# GD32G5x3 register map
File version: 1.0
CPU: CM33 r2p1, little endian, MPU, FPU, 4 interrupt priority bits
Registers are 32-bit, read-write, reset 0x0 unless marked. A register's access mark holds for its fields unless they carry their own. Offsets are from the block's base; [hi:lo] are bit positions; {n}, {i} and the like mark numbered series.

## CAU — Cryptographic Acceleration Unit
Base 0x48021000
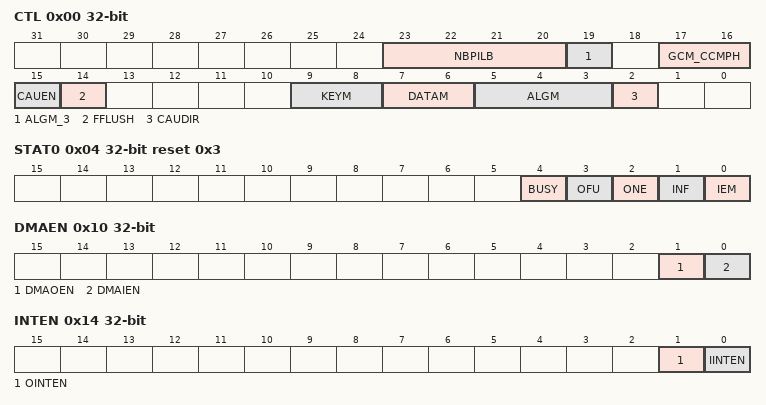
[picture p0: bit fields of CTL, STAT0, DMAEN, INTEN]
0x00 CTL access per field — Control register
  [23:20] NBPILB rw — Number of bytes padding in last block of payload
  [19] ALGM_3 rw — Encryption/decryption algorithm mode bit 3
  [17:16] GCM_CCMPH rw — GCM CCM phase
  [15] CAUEN rw — CAU Enable
  [14] FFLUSH wo — Flush FIFO
  [9:8] KEYM rw — AES key size mode configuration
  [7:6] DATAM rw — Data swapping type mode configuration
  [5:3] ALGM rw — Encryption/decryption algorithm mode bit 0 to bit 2
  [2] CAUDIR rw — CAU direction
0x04 STAT0 ro reset 0x3 — Status register 0
  [4] BUSY — Busy bit
  [3] OFU — Output FIFO is full
  [2] ONE — Output FIFO is not empty
  [1] INF — Input FIFO is not full
  [0] IEM — Input FIFO is empty
0x08 DI — Data input register
  [31:0] DI — Data input
0x0C DO ro — Data output register
  [31:0] DO — Data output
0x10 DMAEN — DMA enable register
  [1] DMAOEN — DMA output enable
  [0] DMAIEN — DMA input enable
0x14 INTEN — Interrupt enable register
  [1] OINTEN — OUT FIFO interrupt enable
  [0] IINTEN — IN FIFO interrupt enable
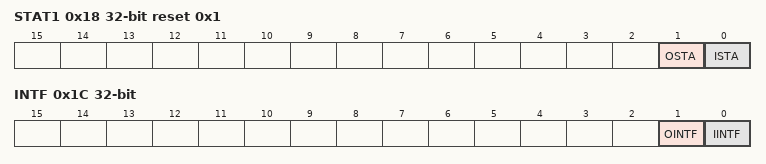
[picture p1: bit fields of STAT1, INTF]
0x18 STAT1 ro reset 0x1 — Status register 1
  [1] OSTA — OUT FIFO interrupt status
  [0] ISTA — IN FIFO interrupt status
0x1C INTF access not given — Interrupt flag register
  [1] OINTF ro — OUT FIFO enabled interrupt flag
  [0] IINTF — IN FIFO enabled interrupt flag
{0x20+8i} KEY{i}H wo (i=0..3) — CAU key register
  [31:0] KEY{i}H — Key for DES,TDES,AES
{0x24+8i} KEY{i}L wo (i=0..3) — CAU key register
  [31:0] KEY{i}L — Key for DES,TDES,AES
0x40 IV0H — CAU initialization register
  [31:0] IV0H — The initialization vector for DES,TDES,AES
0x44 IV0L — CAU initialization register
  [31:0] IV0L — The initialization vector for DES,TDES,AES
0x48 IV1H — CAU initialization register
  [31:0] IV1H — The initialization vector for DES,TDES,AES
0x4C IV1L — CAU initialization register
  [31:0] IV1L — The initialization vector for DES,TDES,AES
{0x50+4i} GCMCCMCTXS{i} (i=0..7) — GCM or CCM mode context switch register {i}
  [31:0] CTX{i} — The internal status of the CAU core
{0x70+4i} GCMCTXS{i} (i=0..7) — GCM mode context switch register {i}
  [31:0] CTX{i} — The internal status of the CAU core

## CLA — Configurable Logic Array
Base 0x40038000
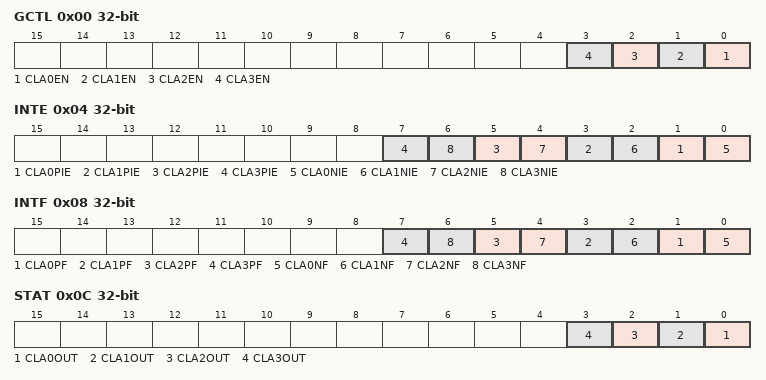
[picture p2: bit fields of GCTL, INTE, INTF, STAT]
0x00 GCTL — Global control register
  [n] CLA{n}EN (n=0..3) — CLA{n} unit enable
0x04 INTE — Interrupt enable register
  [2n+1] CLA{n}PIE (n=0..3) — CLA{n} unit posedge interrupt enable
  [2n] CLA{n}NIE (n=0..3) — CLA{n} unit negedge interrupt enable
0x08 INTF — Interrupt flag register
  [2n+1] CLA{n}PF (n=0..3) — CLA{n} unit posedge flag
  [2n] CLA{n}NF (n=0..3) — CLA{n} unit negedge flag
0x0C STAT ro — Status register
  [n] CLA{n}OUT (n=0..3) — CLA{n} unit output state
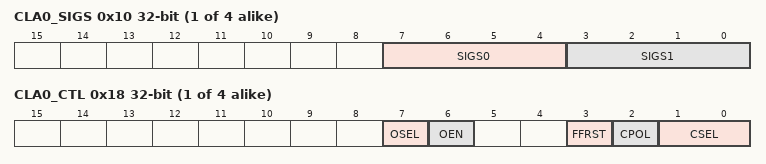
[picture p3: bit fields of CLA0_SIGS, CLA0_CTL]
{0x10+0xC*i} CLA{i}_SIGS (i=0..3) — Signal selection register {i}
  [7:4] SIGS0 — Signal Selector 0 input selection
  [3:0] SIGS1 — Signal Selector 1 input selection
0x14 CLA0_LCUCTL — LCU control register 0
  [7:0] LCUCTL — LCU control
{0x18+0xC*i} CLA{i}_CTL access per field (i=0..3) — Control register {i}
  [7] OSEL rw — Output selection
  [6] OEN rw — Output enable
  [3] FFRST wo — Flip-flop output reset
  [2] CPOL rw — Clock polarity of Flip-flop
  [1:0] CSEL rw — Flip-flop clock source selection
{0x14+0xC*i} CLA{i}_LCUCTL (i=1..3) — LCU control register {i}
  [7:0] LCU — LCU control

## CMP — Comparator
Base 0x40017C00
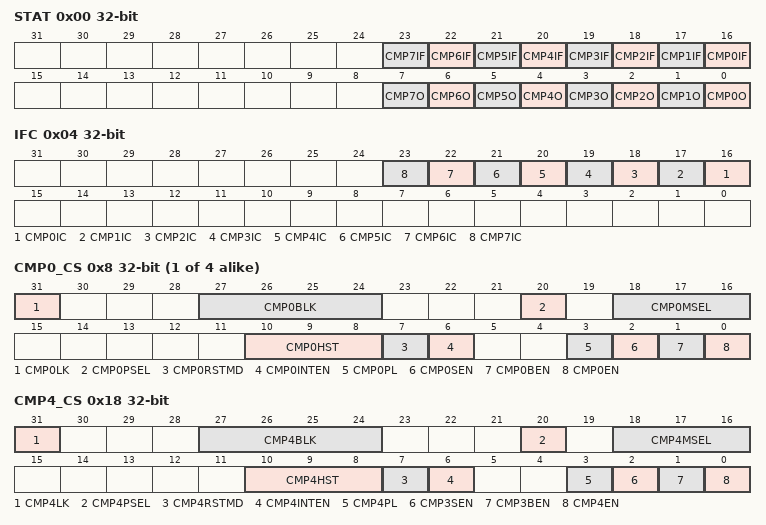
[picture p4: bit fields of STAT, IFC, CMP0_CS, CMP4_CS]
0x00 STAT access per field — CMP status register
  [n+16] CMP{n}IF rw (n=0..7) — CMP{n} interrupt flag
  [n] CMP{n}O ro (n=0..7) — CMP{n} output state
0x04 IFC wo — CMP interrupt flag clear register
  [n+16] CMP{n}IC (n=0..7) — CMP{n} interrupt flag clear
{0x8+4i} CMP{i}_CS (i=0..3) — CMP{i} control/status register
  [31] CMP{i}LK — CMP{i} lock
  [27:24] CMP{i}BLK — CMP{i} output blanking source
  [20] CMP{i}PSEL — CMP{i}_IP input selection
  [18:16] CMP{i}MSEL — CMP{i}_IM internal input selection
  [10:8] CMP{i}HST — CMP{i} hysteresis
  [7] CMP{i}RSTMD — CMP{i} reset mode
  [6] CMP{i}INTEN — CMP{i} interrupt enable
  [3] CMP{i}PL — Polarity of CMP{i} output
  [2] CMP{i}SEN — Voltage scaler enable bit
  [1] CMP{i}BEN — Scaler bridge enable bit
  [0] CMP{i}EN — CMP{i} enable
0x18 CMP4_CS — CMP4 control/status register
  [31] CMP4LK — CMP4 lock
  [27:24] CMP4BLK — CMP4 output blanking source
  [20] CMP4PSEL — CMP4_IP input selection
  [18:16] CMP4MSEL — CMP4_IM internal input selection
  [10:8] CMP4HST — CMP4 hysteresis
  [7] CMP4RSTMD — CMP4 reset mode
  [6] CMP4INTEN — CMP4 interrupt enable
  [3] CMP4PL — Polarity of CMP4 output
  [2] CMP3SEN — Voltage scaler enable bit
  [1] CMP3BEN — Scaler bridge enable bit
  [0] CMP4EN — CMP4 enable
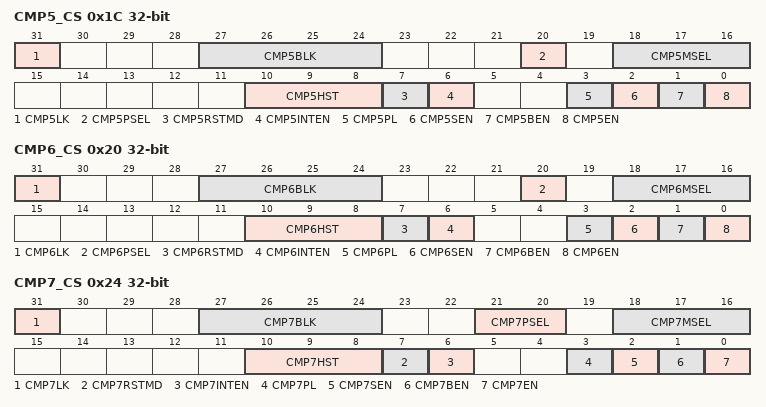
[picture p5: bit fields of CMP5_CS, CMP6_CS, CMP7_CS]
0x1C CMP5_CS — CMP5 control/status register
  [31] CMP5LK — CMP5 lock
  [27:24] CMP5BLK — CMP5 output blanking source
  [20] CMP5PSEL — CMP5_IP input selection
  [18:16] CMP5MSEL — CMP5_IM internal input selection
  [10:8] CMP5HST — CMP5 hysteresis
  [7] CMP5RSTMD — CMP5 reset mode
  [6] CMP5INTEN — CMP5 interrupt enable
  [3] CMP5PL — Polarity of CMP5 output
  [2] CMP5SEN — Voltage scaler enable bit
  [1] CMP5BEN — Scaler bridge enable bit
  [0] CMP5EN — CMP5 enable
0x20 CMP6_CS — CMP6 control/status register
  [31] CMP6LK — CMP6 lock
  [27:24] CMP6BLK — CMP6 output blanking source
  [20] CMP6PSEL — CMP6_IP input selection
  [18:16] CMP6MSEL — CMP6_IM internal input selection
  [10:8] CMP6HST — CMP6 hysteresis
  [7] CMP6RSTMD — CMP6 reset mode
  [6] CMP6INTEN — CMP6 interrupt enable
  [3] CMP6PL — Polarity of CMP6 output
  [2] CMP6SEN — Voltage scaler enable bit
  [1] CMP6BEN — Scaler bridge enable bit
  [0] CMP6EN — CMP6 enable
0x24 CMP7_CS — CMP7 control/status register
  [31] CMP7LK — CMP7 lock
  [27:24] CMP7BLK — CMP7 output blanking source
  [21:20] CMP7PSEL — CMP7_IP input selection
  [18:16] CMP7MSEL — CMP7_IM internal input selection
  [10:8] CMP7HST — CMP7 hysteresis
  [7] CMP7RSTMD — CMP7 reset mode
  [6] CMP7INTEN — CMP7 interrupt enable
  [3] CMP7PL — Polarity of CMP7 output
  [2] CMP7SEN — Voltage scaler enable bit
  [1] CMP7BEN — Scaler bridge enable bit
  [0] CMP7EN — CMP7 enable
